# F28x7x_dev_cfg_regs register map
Vendor: Texas Instruments
Peripheral module from a debugger description file (folder C2000).
Address unit: 16 bits
Registers are 32-bit, read-write, no defined reset value unless marked. A register's access mark holds for its fields unless they carry their own. Offsets are as the file gives them; lines under a group give offsets from that group; [hi:lo] are bit positions; {n}, {i} and the like mark numbered series; 'fields as' and 'values as' point back to an identical list; <NAME> marks a mode.

## DEV_CFG_REGS
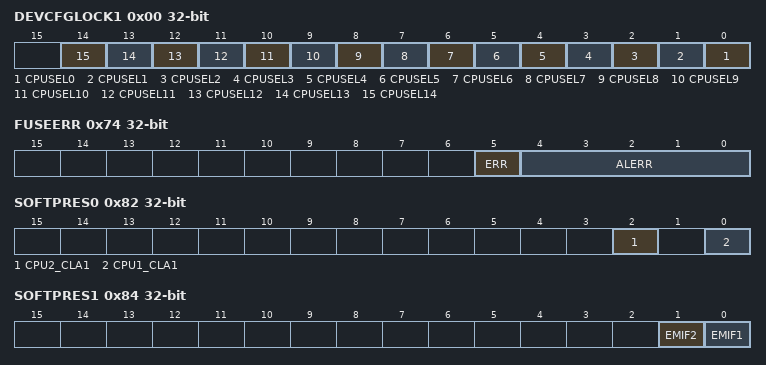
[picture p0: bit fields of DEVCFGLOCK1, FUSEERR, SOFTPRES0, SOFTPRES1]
0x00 DEVCFGLOCK1 — Lock bit for DEVCFG registers
  [n] CPUSEL{n} (n=0..14) — Lock bit for CPUSEL{n} register
0x0C REVID — Device Revision Number
  [31:0] REVID — Device Revision ID
0x74 FUSEERR — e-Fuse error Status register
  [5] ERR — Efuse Self Test Error Status
  [4:0] ALERR — Efuse Autoload Error Status
0x82 SOFTPRES0 — Processing Block Software Reset register
  [2] CPU2_CLA1 — CPU2_CLA1 software reset bit
  [0] CPU1_CLA1 — CPU1_CLA1 software reset bit
0x84 SOFTPRES1 — EMIF Software Reset register
  [1] EMIF2 — EMIF2 software reset bit
  [0] EMIF1 — EMIF1 software reset bit
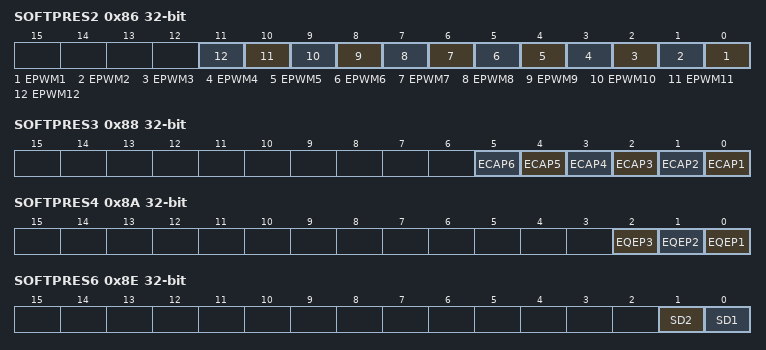
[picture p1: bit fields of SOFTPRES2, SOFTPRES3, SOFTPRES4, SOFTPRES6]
0x86 SOFTPRES2 — Peripheral Software Reset register
  [n-1] EPWM{n} (n=1..12) — EPWM{n} software reset bit
0x88 SOFTPRES3 — Peripheral Software Reset register
  [n-1] ECAP{n} (n=1..6) — ECAP{n} software reset bit
0x8A SOFTPRES4 — Peripheral Software Reset register
  [2] EQEP3 — EQEP3 software reset bit
  [1] EQEP2 — EQEP2 software reset bit
  [0] EQEP1 — EQEP1 software reset bit
0x8C SOFTPRES5 access not given — Peripheral Software Reset register
0x8E SOFTPRES6 — Peripheral Software Reset register
  [1] SD2 — SD2 software reset bit
  [0] SD1 — SD1 software reset bit
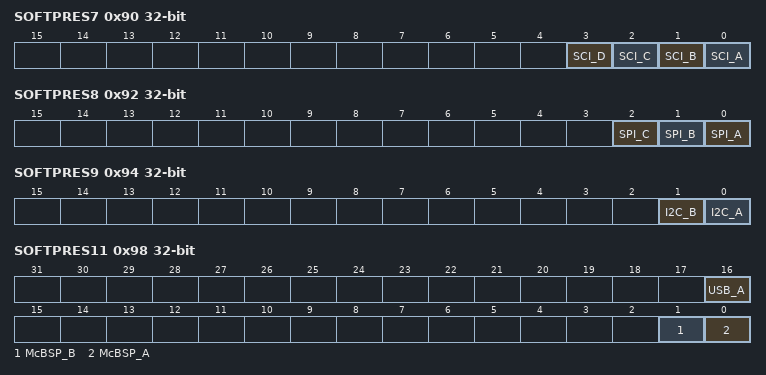
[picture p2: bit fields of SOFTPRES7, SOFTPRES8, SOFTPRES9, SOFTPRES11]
0x90 SOFTPRES7 — Peripheral Software Reset register
  [3] SCI_D — SCI_D software reset bit
  [2] SCI_C — SCI_C software reset bit
  [1] SCI_B — SCI_B software reset bit
  [0] SCI_A — SCI_A software reset bit
0x92 SOFTPRES8 — Peripheral Software Reset register
  [2] SPI_C — SPI_C software reset bit
  [1] SPI_B — SPI_B software reset bit
  [0] SPI_A — SPI_A software reset bit
0x94 SOFTPRES9 — Peripheral Software Reset register
  [1] I2C_B — I2C_B software reset bit
  [0] I2C_A — I2C_A software reset bit
0x98 SOFTPRES11 — Peripheral Software Reset register
  [16] USB_A — USB_A software reset bit
  [1] McBSP_B — McBSP_B software reset bit
  [0] McBSP_A — McBSP_A software reset bit
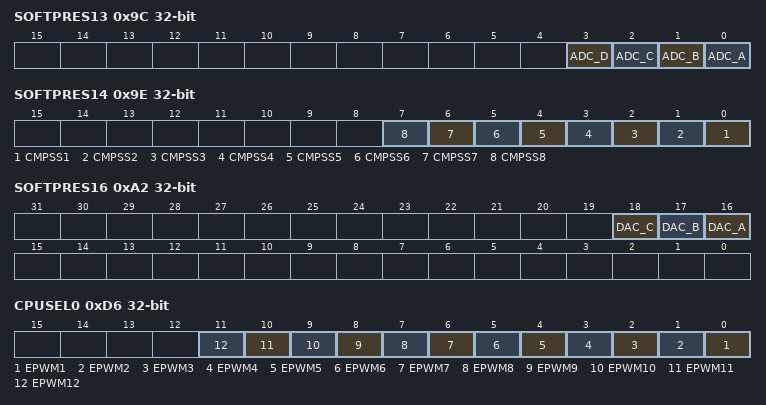
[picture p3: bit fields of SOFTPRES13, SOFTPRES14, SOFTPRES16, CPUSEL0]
0x9C SOFTPRES13 — Peripheral Software Reset register
  [3] ADC_D — ADC_D software reset bit
  [2] ADC_C — ADC_C software reset bit
  [1] ADC_B — ADC_B software reset bit
  [0] ADC_A — ADC_A software reset bit
0x9E SOFTPRES14 — Peripheral Software Reset register
  [n-1] CMPSS{n} (n=1..8) — CMPSS{n} software reset bit
0xA2 SOFTPRES16 — Peripheral Software Reset register
  [18] DAC_C — Buffered_DAC_C software reset bit
  [17] DAC_B — Buffered_DAC_B software reset bit
  [16] DAC_A — Buffered_DAC_A software reset bit
0xD6 CPUSEL0 — CPU Select register for common peripherals
  [n-1] EPWM{n} (n=1..12) — EPWM{n} CPU select bit
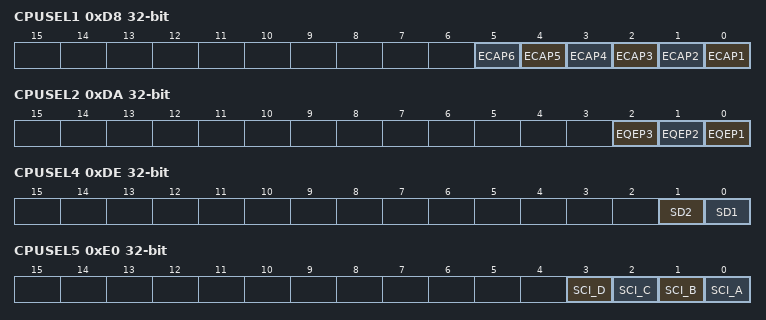
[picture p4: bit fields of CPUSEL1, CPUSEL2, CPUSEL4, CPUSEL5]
0xD8 CPUSEL1 — CPU Select register for common peripherals
  [n-1] ECAP{n} (n=1..6) — ECAP{n} CPU select bit
0xDA CPUSEL2 — CPU Select register for common peripherals
  [2] EQEP3 — EQEP3 CPU select bit
  [1] EQEP2 — EQEP2 CPU select bit
  [0] EQEP1 — EQEP1 CPU select bit
0xDC CPUSEL3 access not given — CPU Select register for common peripherals
0xDE CPUSEL4 — CPU Select register for common peripherals
  [1] SD2 — SD2 CPU select bit
  [0] SD1 — SD1 CPU select bit
0xE0 CPUSEL5 — CPU Select register for common peripherals
  [3] SCI_D — SCI_D CPU select bit
  [2] SCI_C — SCI_C CPU select bit
  [1] SCI_B — SCI_B CPU select bit
  [0] SCI_A — SCI_A CPU select bit
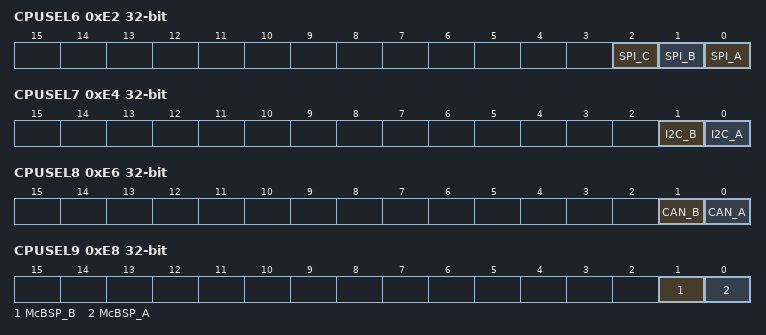
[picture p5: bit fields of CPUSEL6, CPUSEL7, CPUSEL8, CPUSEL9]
0xE2 CPUSEL6 — CPU Select register for common peripherals
  [2] SPI_C — SPI_C CPU select bit
  [1] SPI_B — SPI_B CPU select bit
  [0] SPI_A — SPI_A CPU select bit
0xE4 CPUSEL7 — CPU Select register for common peripherals
  [1] I2C_B — I2C_B CPU select bit
  [0] I2C_A — I2C_A CPU select bit
0xE6 CPUSEL8 — CPU Select register for common peripherals
  [1] CAN_B — CAN_B CPU select bit
  [0] CAN_A — CAN_A CPU select bit
0xE8 CPUSEL9 — CPU Select register for common peripherals
  [1] McBSP_B — McBSP_B CPU select bit
  [0] McBSP_A — McBSP_A CPU select bit
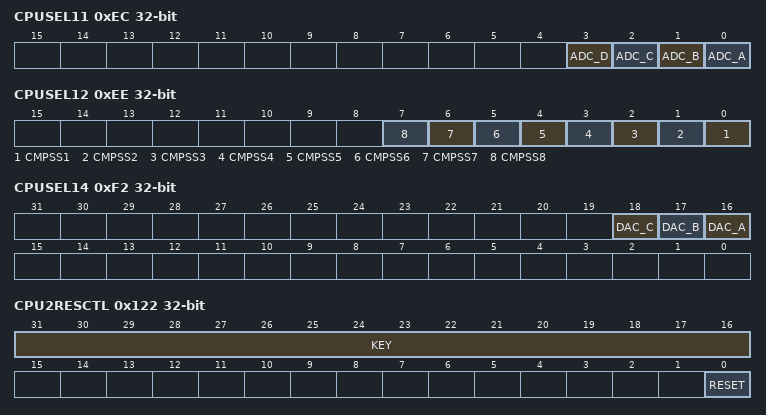
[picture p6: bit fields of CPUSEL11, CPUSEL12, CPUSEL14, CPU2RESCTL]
0xEC CPUSEL11 — CPU Select register for common peripherals
  [3] ADC_D — ADC_D CPU select bit
  [2] ADC_C — ADC_C CPU select bit
  [1] ADC_B — ADC_B CPU select bit
  [0] ADC_A — ADC_A CPU select bit
0xEE CPUSEL12 — CPU Select register for common peripherals
  [n-1] CMPSS{n} (n=1..8) — CMPSS{n} CPU select bit
0xF2 CPUSEL14 — CPU Select register for common peripherals
  [18] DAC_C — Buffered_DAC_C CPU select bit
  [17] DAC_B — Buffered_DAC_B CPU select bit
  [16] DAC_A — Buffered_DAC_A CPU select bit
0x122 CPU2RESCTL — CPU2 Reset Control Register
  [31:16] KEY — Key Qualifier for writes to this register
  [0] RESET — CPU2 Reset Control bit
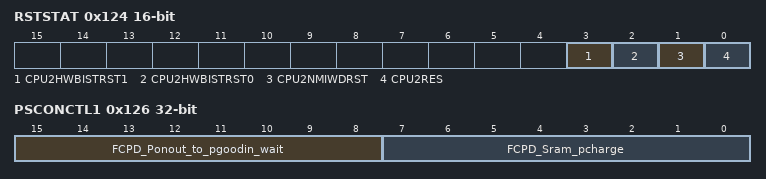
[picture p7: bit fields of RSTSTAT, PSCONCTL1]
0x124 RSTSTAT 16-bit — Reset Status register for secondary C28x CPUs
  [3] CPU2HWBISTRST1 — Tells whether a HWBIST reset was issued to CPU2 or not
  [2] CPU2HWBISTRST0 — Tells whether a HWBIST reset was issued to CPU2 or not
  [1] CPU2NMIWDRST — Tells whether a CPU2.NMIWD reset was issued to CPU2 or not
  [0] CPU2RES — CPU2 Reset Status bit
0x125 LPMSTAT 16-bit — LPM Status Register for secondary C28x CPUs
  [1:0] CPU2LPMSTAT — CPU2 LPM Status
0x126 PSCONCTL1 — Register for PSCON Configuration
  [15:8] FCPD_Ponout_to_pgoodin_wait — FCPD.PSCON.Ponout_to_pgoodin_wait input
  [7:0] FCPD_Sram_pcharge — This bit field is connected to FCPD.PSCON.Sram_pcharge input
0x12C SYSDBGCTL — System Debug Control register
  [0] HIBDIS — HIB Disable configuration when debugger is connected
